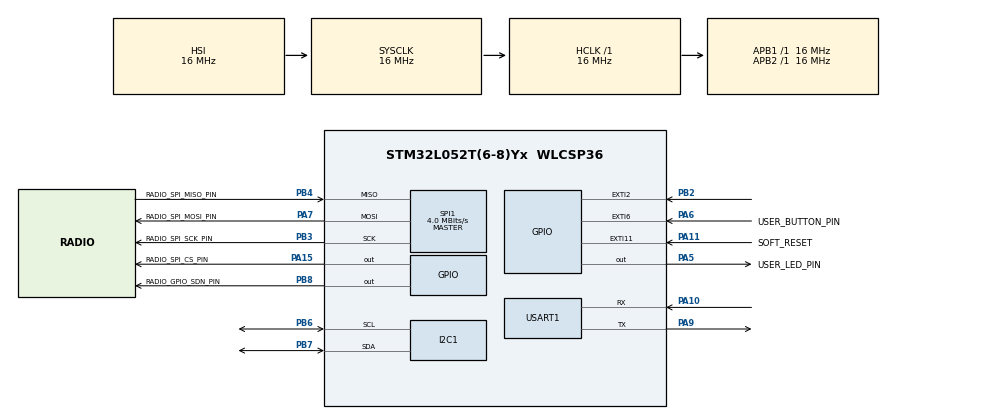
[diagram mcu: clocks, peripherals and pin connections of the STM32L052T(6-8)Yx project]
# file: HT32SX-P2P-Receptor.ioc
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I2C1.Timing=0x00303D5B
Mcu.Family=STM32L0
Mcu.Name=STM32L052T(6-8)Yx
Mcu.Package=WLCSP36
NVIC.EXTI2_3_IRQn=true\:0\:0\:false\:false\:true\:true\:true\:true
NVIC.EXTI4_15_IRQn=true\:2\:0\:true\:false\:true\:true\:true\:true
PA10.Mode=Asynchronous
PA10.Signal=USART1_RX
PA11.GPIO_Label=SOFT_RESET
PA11.GPIO_ModeDefaultEXTI=GPIO_MODE_IT_FALLING
PA11.GPIO_PuPd=GPIO_PULLUP
PA11.Signal=GPXTI11
PA13.Mode=Serial_Wire
PA13.Signal=SYS_SWDIO
PA14.Mode=Serial_Wire
PA14.Signal=SYS_SWCLK
PA15.GPIO_Label=RADIO_SPI_CS_PIN
PA15.GPIO_PuPd=GPIO_PULLUP
PA15.GPIO_Speed=GPIO_SPEED_FREQ_HIGH
PA15.PinState=GPIO_PIN_SET
PA15.Signal=GPIO_Output
PA5.GPIO_Label=USER_LED_PIN
PA5.GPIO_Speed=GPIO_SPEED_FREQ_VERY_HIGH
PA5.Signal=GPIO_Output
PA6.GPIO_Label=USER_BUTTON_PIN
PA6.GPIO_ModeDefaultEXTI=GPIO_MODE_IT_FALLING
PA6.GPIO_PuPd=GPIO_PULLUP
PA6.Signal=GPXTI6
PA7.GPIO_Label=RADIO_SPI_MOSI_PIN
PA7.Mode=Full_Duplex_Master
PA7.Signal=SPI1_MOSI
PA9.Mode=Asynchronous
PA9.Signal=USART1_TX
PB2.GPIO_ModeDefaultEXTI=GPIO_MODE_IT_FALLING
PB2.Signal=GPXTI2
PB3.GPIO_Label=RADIO_SPI_SCK_PIN
PB3.Mode=Full_Duplex_Master
PB3.Signal=SPI1_SCK
PB4.GPIO_Label=RADIO_SPI_MISO_PIN
PB4.Mode=Full_Duplex_Master
PB4.Signal=SPI1_MISO
PB6.Mode=I2C
PB6.Signal=I2C1_SCL
PB7.Mode=I2C
PB7.Signal=I2C1_SDA
PB8.GPIO_Label=RADIO_GPIO_SDN_PIN
PB8.GPIO_Speed=GPIO_SPEED_FREQ_HIGH
PB8.Signal=GPIO_Output
ProjectManager.HeapSize=0x200
ProjectManager.StackSize=0x400
ProjectManager.TargetToolchain=STM32CubeIDE
RCC.AHBFreq_Value=16000000
RCC.APB1Freq_Value=16000000
RCC.APB1TimFreq_Value=16000000
RCC.APB2Freq_Value=16000000
RCC.APB2TimFreq_Value=16000000
RCC.HCLKFreq_Value=16000000
RCC.HSI16_VALUE=16000000
RCC.HSI48_VALUE=48000000
RCC.HSI_VALUE=16000000
RCC.LSE_VALUE=32768
RCC.MSI_VALUE=2097000
RCC.PLLMUL=RCC_PLLMUL_4
RCC.SYSCLKFreq_VALUE=16000000
RCC.SYSCLKSource=RCC_SYSCLKSOURCE_HSI
RCC.VCOOutputFreq_Value=64000000
SPI1.BaudRatePrescaler=SPI_BAUDRATEPRESCALER_4
SPI1.CalculateBaudRate=4.0 MBits/s
SPI1.Direction=SPI_DIRECTION_2LINES
SPI1.Mode=SPI_MODE_MASTER
SPI1.VirtualType=VM_MASTER
USART1.VirtualMode-Asynchronous=VM_ASYNC
board=custom

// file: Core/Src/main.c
/* USER CODE BEGIN Header */
/**
 ******************************************************************************
 * @file           : main.c
 * @brief          : Main program body
 ******************************************************************************
 * @attention
 *
 * <h2><center>&copy; Copyright (c) 2020 STMicroelectronics.
 * All rights reserved.</center></h2>
 *
 * This software component is licensed by ST under BSD 3-Clause license,
 * the "License"; You may not use this file except in compliance with the
 * License. You may obtain a copy of the License at:
 *                        opensource.org/licenses/BSD-3-Clause
 *
 ******************************************************************************
 */
/* USER CODE END Header */
#include "main.h"
#include "i2c.h"
#include "spi.h"
#include "usart.h"
#include "gpio.h"

/* USER CODE BEGIN Includes */
#include "HT_P2P_app.h"
#include "string.h"
/* USER CODE END Includes */

void SystemClock_Config(void);

/* USER CODE BEGIN 0 */

uint8_t RxLength = 0;
uint8_t aTransmitBuffer[TX_BUFFER_SIZE] = {"Hello, World!"};
uint8_t aReceiveBuffer[RX_BUFFER_SIZE] = {0x00};

/* USER CODE END 0 */

int main(void)
{

  /* MCU Configuration--------------------------------------------------------*/

  /* Reset of all peripherals, Initializes the Flash interface and the Systick. */
  HAL_Init();

  /* Configure the system clock */
  SystemClock_Config();

  /* Initialize all configured peripherals */
  MX_GPIO_Init();
  MX_SPI1_Init();
  MX_USART1_UART_Init();
  MX_I2C1_Init();
  /* USER CODE BEGIN 2 */

	printf("HT32SX P2P Application.\n");

	HAL_Radio_Init();

	HT_P2P_Init();

  /* USER CODE END 2 */

  /* Infinite loop */
	while (1)
	{

    /* USER CODE BEGIN 3 */

		P2P_Process(aTransmitBuffer, TX_BUFFER_SIZE, aReceiveBuffer, RxLength);
	}
  /* USER CODE END 3 */
}

void SystemClock_Config(void)
{
  RCC_OscInitTypeDef RCC_OscInitStruct = {0};
  RCC_ClkInitTypeDef RCC_ClkInitStruct = {0};
  RCC_PeriphCLKInitTypeDef PeriphClkInit = {0};

  /** Configure the main internal regulator output voltage
  */
  __HAL_PWR_VOLTAGESCALING_CONFIG(PWR_REGULATOR_VOLTAGE_SCALE1);
  /** Initializes the RCC Oscillators according to the specified parameters
  * in the RCC_OscInitTypeDef structure.
  */
  RCC_OscInitStruct.OscillatorType = RCC_OSCILLATORTYPE_HSI;
  RCC_OscInitStruct.HSIState = RCC_HSI_ON;
  RCC_OscInitStruct.HSICalibrationValue = RCC_HSICALIBRATION_DEFAULT;
  RCC_OscInitStruct.PLL.PLLState = RCC_PLL_NONE;
  if (HAL_RCC_OscConfig(&RCC_OscInitStruct) != HAL_OK)
  {
    Error_Handler();
  }
  /** Initializes the CPU, AHB and APB buses clocks
  */
  RCC_ClkInitStruct.ClockType = RCC_CLOCKTYPE_HCLK|RCC_CLOCKTYPE_SYSCLK
                              |RCC_CLOCKTYPE_PCLK1|RCC_CLOCKTYPE_PCLK2;
  RCC_ClkInitStruct.SYSCLKSource = RCC_SYSCLKSOURCE_HSI;
  RCC_ClkInitStruct.AHBCLKDivider = RCC_SYSCLK_DIV1;
  RCC_ClkInitStruct.APB1CLKDivider = RCC_HCLK_DIV1;
  RCC_ClkInitStruct.APB2CLKDivider = RCC_HCLK_DIV1;

  if (HAL_RCC_ClockConfig(&RCC_ClkInitStruct, FLASH_LATENCY_0) != HAL_OK)
  {
    Error_Handler();
  }
  PeriphClkInit.PeriphClockSelection = RCC_PERIPHCLK_USART1|RCC_PERIPHCLK_I2C1;
  PeriphClkInit.Usart1ClockSelection = RCC_USART1CLKSOURCE_PCLK2;
  PeriphClkInit.I2c1ClockSelection = RCC_I2C1CLKSOURCE_PCLK1;
  if (HAL_RCCEx_PeriphCLKConfig(&PeriphClkInit) != HAL_OK)
  {
    Error_Handler();
  }
}

void Error_Handler(void)
{
}

/************************ (C) COPYRIGHT STMicroelectronics *****END OF FILE****/
